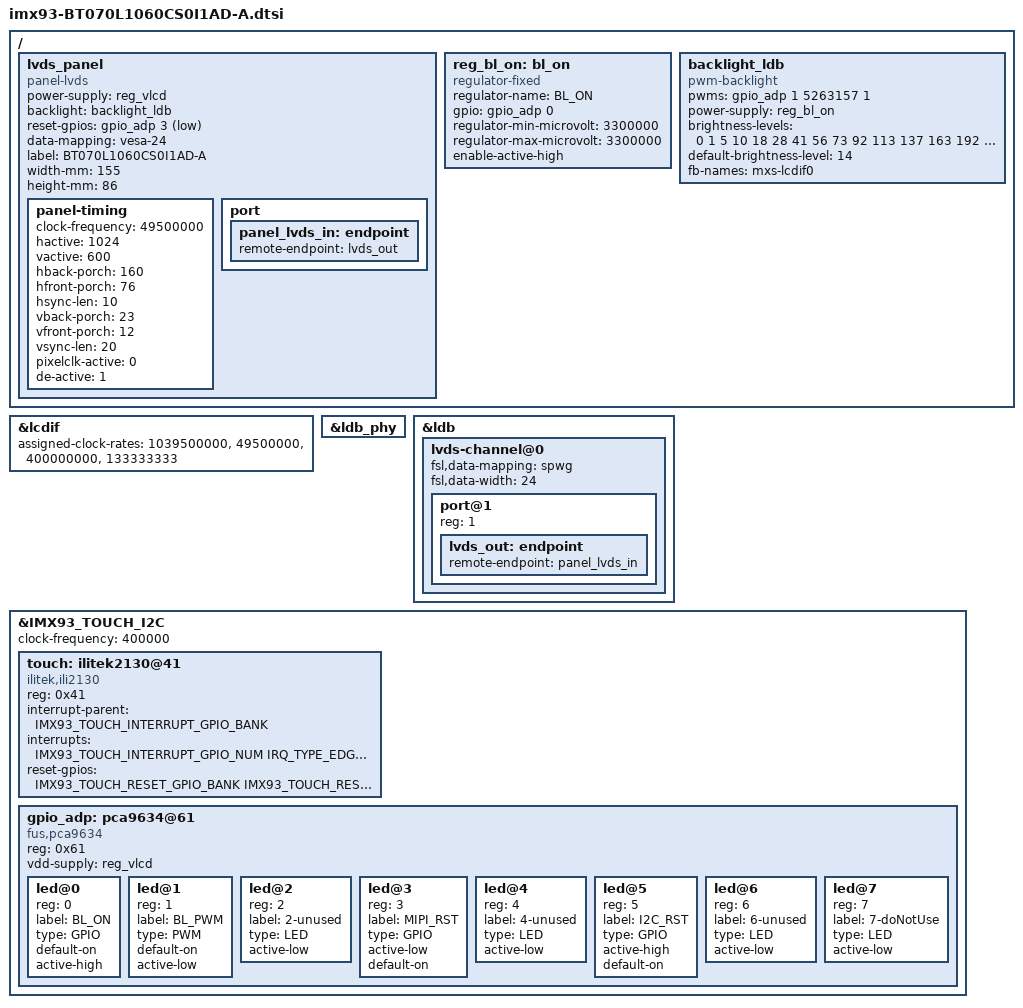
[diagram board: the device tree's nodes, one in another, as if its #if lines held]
// SPDX-License-Identifier: GPL-2.0
/*
* Copyright 2024 F&S Elektronik Systeme GmbH
*
* This program is free software; you can redistribute it and/or modify
* it under the terms of the GNU General Public License version 2 as
* published by the Free Software Foundation.
*
* This program is distributed in the hope that it will be useful,
* but WITHOUT ANY WARRANTY; without even the implied warranty of
* MERCHANTABILITY or FITNESS FOR A PARTICULAR PURPOSE.  See the
* GNU General Public License for more details.
*/

/ {
	lvds_panel {
		compatible = "panel-lvds";
		power-supply = <&reg_vlcd>;
		backlight = <&backlight_ldb>;

		reset-gpios = <&gpio_adp 3 GPIO_ACTIVE_LOW>;

		data-mapping = "vesa-24";
		label = "BT070L1060CS0I1AD-A";
		width-mm = <155>;
		height-mm = <86>;
		status = "okay";

		panel-timing {
			clock-frequency = <49500000>;
			hactive = <1024>;
			vactive = <600>;
			hback-porch = <160>;
			hfront-porch = <76>;
			hsync-len = <10>;
			vback-porch = <23>;
			vfront-porch = <12>;
			vsync-len = <20>;
			pixelclk-active = <0>;
			de-active = <1>;
		};
		port {
			panel_lvds_in: endpoint {
				remote-endpoint = <&lvds_out>;
			};
		};
	};

	reg_bl_on: bl_on {
		compatible = "regulator-fixed";
		regulator-name = "BL_ON";
		gpio = <&gpio_adp 0 GPIO_ACTIVE_HIGH>;
		regulator-min-microvolt = <3300000>;
		regulator-max-microvolt = <3300000>;
		enable-active-high;
	};

	backlight_ldb: backlight_ldb {
		compatible = "pwm-backlight";
		#pwm-cells = <3>;
		pwms = <&gpio_adp 1 5263157 1>;
		power-supply = <&reg_bl_on>;
		brightness-levels = <0 1 5 10 18 28 41 56
			                 73 92 113 137 163 192 222 255>;
		default-brightness-level = <14>;
		fb-names = "mxs-lcdif0";
		status = "okay";
	};

};

/* LVDS */
&lcdif {
	status = "okay";
	assigned-clock-rates = <1039500000>, <49500000>, <400000000>, <133333333>;
};

&ldb_phy {
	status = "okay";
};

&ldb {
	status = "okay";
	lvds-channel@0 {
		fsl,data-mapping = "spwg";
		fsl,data-width = <24>;
		status = "okay";
		port@1 {
			reg = <1>;

			lvds_out: endpoint {
				remote-endpoint = <&panel_lvds_in>;
			};
		};
	};
};

&IMX93_TOUCH_I2C {
	clock-frequency = <400000>;
	/* Ilitek PCAP touch on Touch-Connector (I2C) */
	touch: ilitek2130@41 {
		compatible = "ilitek,ili2130";
		reg = <0x41>;
		interrupt-parent = <&IMX93_TOUCH_INTERRUPT_GPIO_BANK>;
		interrupts = <IMX93_TOUCH_INTERRUPT_GPIO_NUM IRQ_TYPE_EDGE_RISING>;
#ifdef CONFIG_IMX93_TOUCH_RESET
		reset-gpios = <&IMX93_TOUCH_RESET_GPIO_BANK IMX93_TOUCH_RESET_GPIO_NUM GPIO_ACTIVE_LOW>;
#endif /* CONFIG_IMX93_TOUCH_RESET */
	};

    /* use board type specific nodes */
    gpio_adp: pca9634@61 {
		compatible = "fus,pca9634";
		reg = <0x61>;
		vdd-supply = <&reg_vlcd>;
		#address-cells = <1>;
		#size-cells = <0>;
		#pwm-cells = <3>;
		#gpio-cells = <2>;
		led@0 {
			reg = <0>;
			label = "BL_ON";
			type = "GPIO";
			default-on;		/* or: keep-value */
			active-high;
		};
		led@1 {
			reg = <1>;
			label = "BL_PWM";
			type = "PWM";
			default-on;	     /* or: keep-value */
			active-low;
		};
		led@2 {
			reg = <2>;
			label = "2-unused";
			type = "LED";
			active-low;
		};
		led@3 {
			reg = <3>;
			label = "MIPI_RST";
			type = "GPIO";
			active-low;
			default-on;	     /* or: keep-value */
		};
		led@4 {
			reg = <4>;
			label = "4-unused";
			type = "LED";
			active-low;
		};
		led@5 {
			reg = <5>;
			label = "I2C_RST";
			type = "GPIO";
			active-high;
			default-on;     /* or: keep-value */
		};
		led@6 {
			reg = <6>;
			label = "6-unused";
			type = "LED";
			active-low;
		};
		led@7 {
			reg = <7>;
			label = "7-doNotUse";
			type = "LED";
			active-low;
		};
	};
};
